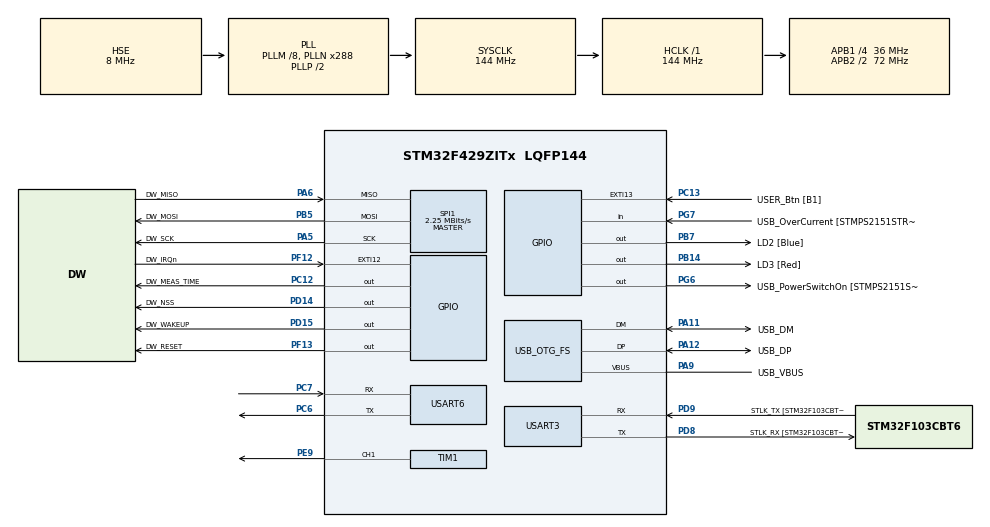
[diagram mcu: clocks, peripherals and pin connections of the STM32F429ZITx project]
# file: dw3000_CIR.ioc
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Dma.Request0=USART3_RX
Dma.Request1=USART3_TX
Dma.USART3_RX.0.Direction=DMA_PERIPH_TO_MEMORY
Dma.USART3_RX.0.FIFOMode=DMA_FIFOMODE_DISABLE
Dma.USART3_RX.0.Instance=DMA1_Stream1
Dma.USART3_RX.0.MemDataAlignment=DMA_MDATAALIGN_BYTE
Dma.USART3_RX.0.MemInc=DMA_MINC_ENABLE
Dma.USART3_RX.0.Mode=DMA_NORMAL
Dma.USART3_RX.0.PeriphDataAlignment=DMA_PDATAALIGN_BYTE
Dma.USART3_RX.0.PeriphInc=DMA_PINC_DISABLE
Dma.USART3_RX.0.Priority=DMA_PRIORITY_LOW
Dma.USART3_TX.1.Direction=DMA_MEMORY_TO_PERIPH
Dma.USART3_TX.1.FIFOMode=DMA_FIFOMODE_DISABLE
Dma.USART3_TX.1.Instance=DMA1_Stream3
Dma.USART3_TX.1.MemDataAlignment=DMA_MDATAALIGN_BYTE
Dma.USART3_TX.1.MemInc=DMA_MINC_ENABLE
Dma.USART3_TX.1.Mode=DMA_NORMAL
Dma.USART3_TX.1.PeriphDataAlignment=DMA_PDATAALIGN_BYTE
Dma.USART3_TX.1.PeriphInc=DMA_PINC_DISABLE
Dma.USART3_TX.1.Priority=DMA_PRIORITY_LOW
Mcu.Family=STM32F4
Mcu.Name=STM32F429ZITx
Mcu.Package=LQFP144
Mcu.UserConstants=LWIP_TIMEVAL_PRIVATE,0
NVIC.DMA1_Stream1_IRQn=true\:5\:0\:true\:true\:true\:2\:true\:true
NVIC.DMA1_Stream3_IRQn=true\:5\:0\:true\:true\:true\:3\:true\:true
NVIC.OTG_FS_IRQn=true\:0\:0\:false\:false\:true\:true\:true
NVIC.PriorityGroup=NVIC_PRIORITYGROUP_4
NVIC.TIM1_CC_IRQn=true\:5\:0\:true\:true\:true\:8\:true\:true
NVIC.TIM6_DAC_IRQn=true\:0\:0\:false\:false\:true\:true\:true
NVIC.TimeBase=TIM6_DAC_IRQn
NVIC.TimeBaseIP=TIM6
NVIC.USART3_IRQn=true\:5\:0\:true\:true\:true\:1\:true\:true
PA1.Signal=ETH_REF_CLK
PA10.GPIO_Label=USB_ID
PA10.Signal=USB_OTG_FS_ID
PA11.GPIO_Label=USB_DM
PA11.Mode=Device_Only
PA11.Signal=USB_OTG_FS_DM
PA12.GPIO_Label=USB_DP
PA12.Mode=Device_Only
PA12.Signal=USB_OTG_FS_DP
PA13.GPIO_Label=TMS
PA13.Mode=Serial_Wire
PA13.Signal=SYS_JTMS-SWDIO
PA14.GPIO_Label=TCK
PA14.Mode=Serial_Wire
PA14.Signal=SYS_JTCK-SWCLK
PA2.GPIO_Label=RMII_MDIO [LAN8742A-CZ-TR_MDIO]
PA2.Signal=ETH_MDIO
PA5.GPIO_Label=DW_SCK
PA5.Mode=Full_Duplex_Master
PA5.Signal=SPI1_SCK
PA6.GPIO_Label=DW_MISO
PA6.Mode=Full_Duplex_Master
PA6.Signal=SPI1_MISO
PA7.Signal=ETH_CRS_DV
PA8.GPIO_Label=USB_SOF [TP1]
PA8.Signal=USB_OTG_FS_SOF
PA9.GPIO_Label=USB_VBUS
PA9.Mode=Activate_VBUS
PA9.Signal=USB_OTG_FS_VBUS
PB13.GPIO_Label=RMII_TXD1 [LAN8742A-CZ-TR_TXD1]
PB13.Signal=ETH_TXD1
PB14.GPIO_Label=LD3 [Red]
PB14.Signal=GPIO_Output
PB5.GPIO_Label=DW_MOSI
PB5.Mode=Full_Duplex_Master
PB5.Signal=SPI1_MOSI
PB7.GPIO_Label=LD2 [Blue]
PB7.Signal=GPIO_Output
PC1.GPIO_Label=RMII_MDC [LAN8742A-CZ-TR_MDC]
PC1.Signal=ETH_MDC
PC12.GPIO_Label=DW_MEAS_TIME
PC12.GPIO_Speed=GPIO_SPEED_FREQ_MEDIUM
PC12.Signal=GPIO_Output
PC13.GPIO_Label=USER_Btn [B1]
PC13.Signal=GPXTI13
PC14/OSC32_IN.Mode=LSE-External-Oscillator
PC14/OSC32_IN.Signal=RCC_OSC32_IN
PC15/OSC32_OUT.Mode=LSE-External-Oscillator
PC15/OSC32_OUT.Signal=RCC_OSC32_OUT
PC4.GPIO_Label=RMII_RXD0 [LAN8742A-CZ-TR_RXD0]
PC4.Signal=ETH_RXD0
PC5.GPIO_Label=RMII_RXD1 [LAN8742A-CZ-TR_RXD1]
PC5.Signal=ETH_RXD1
PC6.Mode=Asynchronous
PC6.Signal=USART6_TX
PC7.Mode=Asynchronous
PC7.Signal=USART6_RX
PD14.GPIO_Label=DW_NSS
PD14.GPIO_PuPd=GPIO_PULLUP
PD14.GPIO_Speed=GPIO_SPEED_FREQ_MEDIUM
PD14.PinState=GPIO_PIN_SET
PD14.Signal=GPIO_Output
PD15.GPIO_Label=DW_WAKEUP
PD15.GPIO_Speed=GPIO_SPEED_FREQ_MEDIUM
PD15.Signal=GPIO_Output
PD8.GPIO_Label=STLK_RX [STM32F103CBT6_PA3]
PD8.Mode=Asynchronous
PD8.Signal=USART3_TX
PD9.GPIO_Label=STLK_TX [STM32F103CBT6_PA2]
PD9.Mode=Asynchronous
PD9.Signal=USART3_RX
PE9.Signal=S_TIM1_CH1
PF12.GPIO_Label=DW_IRQn
PF12.GPIO_PuPd=GPIO_PULLDOWN
PF12.Signal=GPXTI12
PF13.GPIO_Label=DW_RESET
PF13.GPIO_ModeDefaultOutputPP=GPIO_MODE_OUTPUT_OD
PF13.GPIO_Speed=GPIO_SPEED_FREQ_MEDIUM
PF13.Signal=GPIO_Output
PG11.GPIO_Label=RMII_TX_EN [LAN8742A-CZ-TR_TXEN]
PG11.Signal=ETH_TX_EN
PG13.GPIO_Label=RMII_TXD0 [LAN8742A-CZ-TR_TXD0]
PG13.Signal=ETH_TXD0
PG6.GPIO_Label=USB_PowerSwitchOn [STMPS2151STR_EN]
PG6.Signal=GPIO_Output
PG7.GPIO_Label=USB_OverCurrent [STMPS2151STR_FAULT]
PG7.Signal=GPIO_Input
PH0/OSC_IN.GPIO_Label=MCO [STM32F103CBT6_PA8]
PH0/OSC_IN.Mode=HSE-External-Clock-Source
PH0/OSC_IN.Signal=RCC_OSC_IN
PH1/OSC_OUT.Mode=HSE-External-Clock-Source
PH1/OSC_OUT.Signal=RCC_OSC_OUT
ProjectManager.HeapSize=0x200
ProjectManager.StackSize=0x400
ProjectManager.TargetToolchain=SW4STM32
RCC.48MHZClocksFreq_Value=48000000
RCC.AHBFreq_Value=144000000
RCC.APB1CLKDivider=RCC_HCLK_DIV4
RCC.APB1Freq_Value=36000000
RCC.APB1TimFreq_Value=72000000
RCC.APB2CLKDivider=RCC_HCLK_DIV2
RCC.APB2Freq_Value=72000000
RCC.APB2TimFreq_Value=144000000
RCC.CortexFreq_Value=144000000
RCC.HCLKFreq_Value=144000000
RCC.HSE_VALUE=8000000
RCC.HSI_VALUE=16000000
RCC.PLLM=8
RCC.PLLMUL=RCC_PLL_MUL9
RCC.PLLN=288
RCC.PLLQ=6
RCC.PRESCALERUSB=RCC_USBCLKSOURCE_PLL_DIV1_5
RCC.SYSCLKFreq_VALUE=144000000
RCC.SYSCLKSource=RCC_SYSCLKSOURCE_PLLCLK
RCC.SYSCLKSourceVirtual=RCC_SYSCLKSOURCE_PLLCLK
RCC.USBFreq_Value=48000000
RCC.VCOOutputFreq_Value=288000000
SH.S_TIM1_CH1.0=TIM1_CH1,Output Compare1 CH1
SPI1.BaudRatePrescaler=SPI_BAUDRATEPRESCALER_32
SPI1.CalculateBaudRate=2.25 MBits/s
SPI1.Direction=SPI_DIRECTION_2LINES
SPI1.Mode=SPI_MODE_MASTER
SPI1.VirtualType=VM_MASTER
TIM1.Channel-Output\ Compare1\ CH1=TIM_CHANNEL_1
TIM1.ClockDivision=TIM_CLOCKDIVISION_DIV2
TIM1.Period=65535
USART3.VirtualMode=VM_ASYNC
USART6.VirtualMode=VM_ASYNC
USB_DEVICE.CLASS_NAME_FS=CDC
USB_DEVICE.VirtualMode-CDC_FS=Cdc
USB_DEVICE.VirtualModeFS=Cdc_FS
USB_OTG_FS.VirtualMode=Device_Only
VP_RNG_VS_RNG.Mode=RNG_Activate
VP_SYS_VS_tim6.Mode=TIM6
VP_TIM1_VS_ClockSourceINT.Mode=Internal
VP_TIM1_VS_ClockSourceITR.Mode=TriggerSource_ITR0
VP_TIM1_VS_ControllerModeTrigger.Mode=Trigger Mode
VP_USB_DEVICE_VS_USB_DEVICE_CDC_FS.Mode=CDC_FS
board=NUCLEO-F429ZI

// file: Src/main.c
/* USER CODE BEGIN Header */
/**
  ******************************************************************************
  * @file           : main.c
  * @brief          : Main program body
  ******************************************************************************
  * @attention
  *
  * <h2><center>&copy; Copyright (c) 2021 STMicroelectronics.
  * All rights reserved.</center></h2>
  *
  * This software component is licensed by ST under Ultimate Liberty license
  * SLA0044, the "License"; You may not use this file except in compliance with
  * the License. You may obtain a copy of the License at:
  *                             www.st.com/SLA0044
  *
  ******************************************************************************
  */
/* USER CODE END Header */
#include <main.h>
#include <stm32f4xx_hal.h>
#include <usb_device.h>
#include <port.h>
#include "examples_defines.h"

RNG_HandleTypeDef hrng;

SPI_HandleTypeDef hspi1;

TIM_HandleTypeDef htim1;

UART_HandleTypeDef huart3;
UART_HandleTypeDef huart6;
DMA_HandleTypeDef hdma_usart3_rx;
DMA_HandleTypeDef hdma_usart3_tx;

/* USER CODE BEGIN PV */
#define UNIT_TEST 0
/* USER CODE END PV */

void SystemClock_Config(void);
static void MX_GPIO_Init(void);
static void MX_DMA_Init(void);
static void MX_TIM1_Init(void);
static void MX_USART3_UART_Init(void);
static void MX_SPI1_Init(void);
static void MX_RNG_Init(void);
static void MX_USART6_UART_Init(void);
static void MX_NVIC_Init(void);

void HAL_TIM_MspPostInit(TIM_HandleTypeDef *htim);

extern example_ptr example_pointer;

extern int unit_test_main(void);
extern uint8_t CDC_Transmit_FS(uint8_t* Buf, uint16_t Len);

/*! ------------------------------------------------------------------------------------------------------------------
* @fn test_run_info()
*
* @brief  This gets run info from a test and sends it through virtual COM port.
*
* @param data - Message data, this data should be NULL string.
*
* output parameters
*
* no return value
*/
void test_run_info(unsigned char *data)
{
    uint16_t    data_length;

    data_length=strlen((const char *)data);
    CDC_Transmit_FS(data, data_length);/*Transmit the data through USB - Virtual port*/
    //CDC_Transmit_FS((uint8_t*)"\n\r", 2);/*Transmit end of line through USB - Virtual port*/
}

int main(void)
{
  /* MCU Configuration--------------------------------------------------------*/

  /* Reset of all peripherals, Initializes the Flash interface and the Systick. */
  HAL_Init();

  /* Configure the system clock */
  SystemClock_Config();

  /* Initialize all configured peripherals */
  MX_GPIO_Init();
  MX_DMA_Init();
  MX_TIM1_Init();
  MX_USART3_UART_Init();
  MX_USB_DEVICE_Init();
  MX_SPI1_Init();
  MX_RNG_Init();
  MX_USART6_UART_Init();

  /* Initialize interrupts */
  MX_NVIC_Init();

  /* Infinite loop */
  /* USER CODE BEGIN WHILE */
  while (1)
  {
    /* USER CODE END WHILEafafs */
	 ss_twr_anchor();

  }
}

void SystemClock_Config(void)
{
  RCC_OscInitTypeDef RCC_OscInitStruct = {0};
  RCC_ClkInitTypeDef RCC_ClkInitStruct = {0};

  /** Configure the main internal regulator output voltage
  */
  __HAL_RCC_PWR_CLK_ENABLE();
  __HAL_PWR_VOLTAGESCALING_CONFIG(PWR_REGULATOR_VOLTAGE_SCALE1);
  /** Initializes the RCC Oscillators according to the specified parameters
  * in the RCC_OscInitTypeDef structure.
  */
  RCC_OscInitStruct.OscillatorType = RCC_OSCILLATORTYPE_HSE;
  RCC_OscInitStruct.HSEState = RCC_HSE_BYPASS;
  RCC_OscInitStruct.PLL.PLLState = RCC_PLL_ON;
  RCC_OscInitStruct.PLL.PLLSource = RCC_PLLSOURCE_HSE;
  RCC_OscInitStruct.PLL.PLLM = 8;
  RCC_OscInitStruct.PLL.PLLN = 288;
  RCC_OscInitStruct.PLL.PLLP = RCC_PLLP_DIV2;
  RCC_OscInitStruct.PLL.PLLQ = 6;
  if (HAL_RCC_OscConfig(&RCC_OscInitStruct) != HAL_OK)
  {
    Error_Handler();
  }
  /** Initializes the CPU, AHB and APB buses clocks
  */
  RCC_ClkInitStruct.ClockType = RCC_CLOCKTYPE_HCLK|RCC_CLOCKTYPE_SYSCLK
                              |RCC_CLOCKTYPE_PCLK1|RCC_CLOCKTYPE_PCLK2;
  RCC_ClkInitStruct.SYSCLKSource = RCC_SYSCLKSOURCE_PLLCLK;
  RCC_ClkInitStruct.AHBCLKDivider = RCC_SYSCLK_DIV1;
  RCC_ClkInitStruct.APB1CLKDivider = RCC_HCLK_DIV4;
  RCC_ClkInitStruct.APB2CLKDivider = RCC_HCLK_DIV2;

  if (HAL_RCC_ClockConfig(&RCC_ClkInitStruct, FLASH_LATENCY_4) != HAL_OK)
  {
    Error_Handler();
  }
}

/**
  * @brief NVIC Configuration.
  * @retval None
  */
static void MX_NVIC_Init(void)
{
  /* USART3_IRQn interrupt configuration */
  HAL_NVIC_SetPriority(USART3_IRQn, 5, 0);
  HAL_NVIC_EnableIRQ(USART3_IRQn);
  /* DMA1_Stream1_IRQn interrupt configuration */
  HAL_NVIC_SetPriority(DMA1_Stream1_IRQn, 5, 0);
  HAL_NVIC_EnableIRQ(DMA1_Stream1_IRQn);
  /* DMA1_Stream3_IRQn interrupt configuration */
  HAL_NVIC_SetPriority(DMA1_Stream3_IRQn, 5, 0);
  HAL_NVIC_EnableIRQ(DMA1_Stream3_IRQn);
  /* TIM1_CC_IRQn interrupt configuration */
  HAL_NVIC_SetPriority(TIM1_CC_IRQn, 5, 0);
  HAL_NVIC_EnableIRQ(TIM1_CC_IRQn);
}

static void MX_RNG_Init(void)
{

  hrng.Instance = RNG;
  if (HAL_RNG_Init(&hrng) != HAL_OK)
  {
    Error_Handler();
  }

}

static void MX_SPI1_Init(void)
{

  /* SPI1 parameter configuration*/
  hspi1.Instance = SPI1;
  hspi1.Init.Mode = SPI_MODE_MASTER;
  hspi1.Init.Direction = SPI_DIRECTION_2LINES;
  hspi1.Init.DataSize = SPI_DATASIZE_8BIT;
  hspi1.Init.CLKPolarity = SPI_POLARITY_LOW;
  hspi1.Init.CLKPhase = SPI_PHASE_1EDGE;
  hspi1.Init.NSS = SPI_NSS_SOFT;
  hspi1.Init.BaudRatePrescaler = SPI_BAUDRATEPRESCALER_32;
  hspi1.Init.FirstBit = SPI_FIRSTBIT_MSB;
  hspi1.Init.TIMode = SPI_TIMODE_DISABLE;
  hspi1.Init.CRCCalculation = SPI_CRCCALCULATION_DISABLE;
  hspi1.Init.CRCPolynomial = 10;
  if (HAL_SPI_Init(&hspi1) != HAL_OK)
  {
    Error_Handler();
  }

}

static void MX_TIM1_Init(void)
{

  TIM_ClockConfigTypeDef sClockSourceConfig = {0};
  TIM_SlaveConfigTypeDef sSlaveConfig = {0};
  TIM_MasterConfigTypeDef sMasterConfig = {0};
  TIM_OC_InitTypeDef sConfigOC = {0};
  TIM_BreakDeadTimeConfigTypeDef sBreakDeadTimeConfig = {0};

  htim1.Instance = TIM1;
  htim1.Init.Prescaler = 0;
  htim1.Init.CounterMode = TIM_COUNTERMODE_UP;
  htim1.Init.Period = 65535;
  htim1.Init.ClockDivision = TIM_CLOCKDIVISION_DIV2;
  htim1.Init.RepetitionCounter = 0;
  htim1.Init.AutoReloadPreload = TIM_AUTORELOAD_PRELOAD_DISABLE;
  if (HAL_TIM_Base_Init(&htim1) != HAL_OK)
  {
    Error_Handler();
  }
  sClockSourceConfig.ClockSource = TIM_CLOCKSOURCE_INTERNAL;
  if (HAL_TIM_ConfigClockSource(&htim1, &sClockSourceConfig) != HAL_OK)
  {
    Error_Handler();
  }
  if (HAL_TIM_OC_Init(&htim1) != HAL_OK)
  {
    Error_Handler();
  }
  sSlaveConfig.SlaveMode = TIM_SLAVEMODE_TRIGGER;
  sSlaveConfig.InputTrigger = TIM_TS_ITR0;
  if (HAL_TIM_SlaveConfigSynchro(&htim1, &sSlaveConfig) != HAL_OK)
  {
    Error_Handler();
  }
  sMasterConfig.MasterOutputTrigger = TIM_TRGO_RESET;
  sMasterConfig.MasterSlaveMode = TIM_MASTERSLAVEMODE_DISABLE;
  if (HAL_TIMEx_MasterConfigSynchronization(&htim1, &sMasterConfig) != HAL_OK)
  {
    Error_Handler();
  }
  sConfigOC.OCMode = TIM_OCMODE_TIMING;
  sConfigOC.Pulse = 0;
  sConfigOC.OCPolarity = TIM_OCPOLARITY_HIGH;
  sConfigOC.OCNPolarity = TIM_OCNPOLARITY_HIGH;
  sConfigOC.OCFastMode = TIM_OCFAST_DISABLE;
  sConfigOC.OCIdleState = TIM_OCIDLESTATE_RESET;
  sConfigOC.OCNIdleState = TIM_OCNIDLESTATE_RESET;
  if (HAL_TIM_OC_ConfigChannel(&htim1, &sConfigOC, TIM_CHANNEL_1) != HAL_OK)
  {
    Error_Handler();
  }
  sBreakDeadTimeConfig.OffStateRunMode = TIM_OSSR_DISABLE;
  sBreakDeadTimeConfig.OffStateIDLEMode = TIM_OSSI_DISABLE;
  sBreakDeadTimeConfig.LockLevel = TIM_LOCKLEVEL_OFF;
  sBreakDeadTimeConfig.DeadTime = 0;
  sBreakDeadTimeConfig.BreakState = TIM_BREAK_DISABLE;
  sBreakDeadTimeConfig.BreakPolarity = TIM_BREAKPOLARITY_HIGH;
  sBreakDeadTimeConfig.AutomaticOutput = TIM_AUTOMATICOUTPUT_DISABLE;
  if (HAL_TIMEx_ConfigBreakDeadTime(&htim1, &sBreakDeadTimeConfig) != HAL_OK)
  {
    Error_Handler();
  }
  HAL_TIM_MspPostInit(&htim1);

}

static void MX_USART3_UART_Init(void)
{

  huart3.Instance = USART3;
  huart3.Init.BaudRate = 115200;
  huart3.Init.WordLength = UART_WORDLENGTH_8B;
  huart3.Init.StopBits = UART_STOPBITS_1;
  huart3.Init.Parity = UART_PARITY_NONE;
  huart3.Init.Mode = UART_MODE_TX_RX;
  huart3.Init.HwFlowCtl = UART_HWCONTROL_NONE;
  huart3.Init.OverSampling = UART_OVERSAMPLING_16;
  if (HAL_UART_Init(&huart3) != HAL_OK)
  {
    Error_Handler();
  }

}

static void MX_USART6_UART_Init(void)
{

  huart6.Instance = USART6;
  huart6.Init.BaudRate = 115200;
  huart6.Init.WordLength = UART_WORDLENGTH_8B;
  huart6.Init.StopBits = UART_STOPBITS_1;
  huart6.Init.Parity = UART_PARITY_NONE;
  huart6.Init.Mode = UART_MODE_TX_RX;
  huart6.Init.HwFlowCtl = UART_HWCONTROL_NONE;
  huart6.Init.OverSampling = UART_OVERSAMPLING_16;
  if (HAL_UART_Init(&huart6) != HAL_OK)
  {
    Error_Handler();
  }

}

static void MX_DMA_Init(void)
{

  /* DMA controller clock enable */
  __HAL_RCC_DMA1_CLK_ENABLE();

}

static void MX_GPIO_Init(void)
{
  GPIO_InitTypeDef GPIO_InitStruct = {0};

  /* GPIO Ports Clock Enable */
  __HAL_RCC_GPIOC_CLK_ENABLE();
  __HAL_RCC_GPIOH_CLK_ENABLE();
  __HAL_RCC_GPIOA_CLK_ENABLE();
  __HAL_RCC_GPIOF_CLK_ENABLE();
  __HAL_RCC_GPIOE_CLK_ENABLE();
  __HAL_RCC_GPIOB_CLK_ENABLE();
  __HAL_RCC_GPIOD_CLK_ENABLE();
  __HAL_RCC_GPIOG_CLK_ENABLE();

  /*Configure GPIO pin Output Level */
  HAL_GPIO_WritePin(DW_RESET_GPIO_Port, DW_RESET_Pin, GPIO_PIN_RESET);

  /*Configure GPIO pin Output Level */
  HAL_GPIO_WritePin(GPIOB, LD3_Pin|LD2_Pin, GPIO_PIN_RESET);

  /*Configure GPIO pin Output Level */
  HAL_GPIO_WritePin(DW_NSS_GPIO_Port, DW_NSS_Pin, GPIO_PIN_SET);

  /*Configure GPIO pin Output Level */
  HAL_GPIO_WritePin(DW_WAKEUP_GPIO_Port, DW_WAKEUP_Pin, GPIO_PIN_RESET);

  /*Configure GPIO pin Output Level */
  HAL_GPIO_WritePin(USB_PowerSwitchOn_GPIO_Port, USB_PowerSwitchOn_Pin, GPIO_PIN_RESET);

  /*Configure GPIO pin Output Level */
  HAL_GPIO_WritePin(DW_MEAS_TIME_GPIO_Port, DW_MEAS_TIME_Pin, GPIO_PIN_RESET);

  /*Configure GPIO pin : USER_Btn_Pin */
  GPIO_InitStruct.Pin = USER_Btn_Pin;
  GPIO_InitStruct.Mode = GPIO_MODE_IT_RISING;
  GPIO_InitStruct.Pull = GPIO_NOPULL;
  HAL_GPIO_Init(USER_Btn_GPIO_Port, &GPIO_InitStruct);

  /*Configure GPIO pins : RMII_MDC_Pin RMII_RXD0_Pin RMII_RXD1_Pin */
  GPIO_InitStruct.Pin = RMII_MDC_Pin|RMII_RXD0_Pin|RMII_RXD1_Pin;
  GPIO_InitStruct.Mode = GPIO_MODE_AF_PP;
  GPIO_InitStruct.Pull = GPIO_NOPULL;
  GPIO_InitStruct.Speed = GPIO_SPEED_FREQ_VERY_HIGH;
  GPIO_InitStruct.Alternate = GPIO_AF11_ETH;
  HAL_GPIO_Init(GPIOC, &GPIO_InitStruct);

  /*Configure GPIO pins : PA1 RMII_MDIO_Pin PA7 */
  GPIO_InitStruct.Pin = GPIO_PIN_1|RMII_MDIO_Pin|GPIO_PIN_7;
  GPIO_InitStruct.Mode = GPIO_MODE_AF_PP;
  GPIO_InitStruct.Pull = GPIO_NOPULL;
  GPIO_InitStruct.Speed = GPIO_SPEED_FREQ_VERY_HIGH;
  GPIO_InitStruct.Alternate = GPIO_AF11_ETH;
  HAL_GPIO_Init(GPIOA, &GPIO_InitStruct);

  /*Configure GPIO pin : DW_IRQn_Pin */
  GPIO_InitStruct.Pin = DW_IRQn_Pin;
  GPIO_InitStruct.Mode = GPIO_MODE_IT_RISING;
  GPIO_InitStruct.Pull = GPIO_PULLDOWN;
  HAL_GPIO_Init(DW_IRQn_GPIO_Port, &GPIO_InitStruct);

  /*Configure GPIO pin : DW_RESET_Pin */
  GPIO_InitStruct.Pin = DW_RESET_Pin;
  GPIO_InitStruct.Mode = GPIO_MODE_OUTPUT_OD;
  GPIO_InitStruct.Pull = GPIO_NOPULL;
  GPIO_InitStruct.Speed = GPIO_SPEED_FREQ_MEDIUM;
  HAL_GPIO_Init(DW_RESET_GPIO_Port, &GPIO_InitStruct);

  /*Configure GPIO pin : RMII_TXD1_Pin */
  GPIO_InitStruct.Pin = RMII_TXD1_Pin;
  GPIO_InitStruct.Mode = GPIO_MODE_AF_PP;
  GPIO_InitStruct.Pull = GPIO_NOPULL;
  GPIO_InitStruct.Speed = GPIO_SPEED_FREQ_VERY_HIGH;
  GPIO_InitStruct.Alternate = GPIO_AF11_ETH;
  HAL_GPIO_Init(RMII_TXD1_GPIO_Port, &GPIO_InitStruct);

  /*Configure GPIO pins : LD3_Pin LD2_Pin */
  GPIO_InitStruct.Pin = LD3_Pin|LD2_Pin;
  GPIO_InitStruct.Mode = GPIO_MODE_OUTPUT_PP;
  GPIO_InitStruct.Pull = GPIO_NOPULL;
  GPIO_InitStruct.Speed = GPIO_SPEED_FREQ_LOW;
  HAL_GPIO_Init(GPIOB, &GPIO_InitStruct);

  /*Configure GPIO pin : DW_NSS_Pin */
  GPIO_InitStruct.Pin = DW_NSS_Pin;
  GPIO_InitStruct.Mode = GPIO_MODE_OUTPUT_PP;
  GPIO_InitStruct.Pull = GPIO_PULLUP;
  GPIO_InitStruct.Speed = GPIO_SPEED_FREQ_MEDIUM;
  HAL_GPIO_Init(DW_NSS_GPIO_Port, &GPIO_InitStruct);

  /*Configure GPIO pin : DW_WAKEUP_Pin */
  GPIO_InitStruct.Pin = DW_WAKEUP_Pin;
  GPIO_InitStruct.Mode = GPIO_MODE_OUTPUT_PP;
  GPIO_InitStruct.Pull = GPIO_NOPULL;
  GPIO_InitStruct.Speed = GPIO_SPEED_FREQ_MEDIUM;
  HAL_GPIO_Init(DW_WAKEUP_GPIO_Port, &GPIO_InitStruct);

  /*Configure GPIO pin : USB_PowerSwitchOn_Pin */
  GPIO_InitStruct.Pin = USB_PowerSwitchOn_Pin;
  GPIO_InitStruct.Mode = GPIO_MODE_OUTPUT_PP;
  GPIO_InitStruct.Pull = GPIO_NOPULL;
  GPIO_InitStruct.Speed = GPIO_SPEED_FREQ_LOW;
  HAL_GPIO_Init(USB_PowerSwitchOn_GPIO_Port, &GPIO_InitStruct);

  /*Configure GPIO pin : USB_OverCurrent_Pin */
  GPIO_InitStruct.Pin = USB_OverCurrent_Pin;
  GPIO_InitStruct.Mode = GPIO_MODE_INPUT;
  GPIO_InitStruct.Pull = GPIO_NOPULL;
  HAL_GPIO_Init(USB_OverCurrent_GPIO_Port, &GPIO_InitStruct);

  /*Configure GPIO pin : DW_MEAS_TIME_Pin */
  GPIO_InitStruct.Pin = DW_MEAS_TIME_Pin;
  GPIO_InitStruct.Mode = GPIO_MODE_OUTPUT_PP;
  GPIO_InitStruct.Pull = GPIO_NOPULL;
  GPIO_InitStruct.Speed = GPIO_SPEED_FREQ_MEDIUM;
  HAL_GPIO_Init(DW_MEAS_TIME_GPIO_Port, &GPIO_InitStruct);

  /*Configure GPIO pins : RMII_TX_EN_Pin RMII_TXD0_Pin */
  GPIO_InitStruct.Pin = RMII_TX_EN_Pin|RMII_TXD0_Pin;
  GPIO_InitStruct.Mode = GPIO_MODE_AF_PP;
  GPIO_InitStruct.Pull = GPIO_NOPULL;
  GPIO_InitStruct.Speed = GPIO_SPEED_FREQ_VERY_HIGH;
  GPIO_InitStruct.Alternate = GPIO_AF11_ETH;
  HAL_GPIO_Init(GPIOG, &GPIO_InitStruct);

}

 /**
  * @brief  Period elapsed callback in non blocking mode
  * @note   This function is called  when TIM6 interrupt took place, inside
  * HAL_TIM_IRQHandler(). It makes a direct call to HAL_IncTick() to increment
  * a global variable "uwTick" used as application time base.
  * @param  htim : TIM handle
  * @retval None
  */
void HAL_TIM_PeriodElapsedCallback(TIM_HandleTypeDef *htim)
{
  if (htim->Instance == TIM6) {
    HAL_IncTick();
  }
}

void Error_Handler(void)
{
  __disable_irq();
  while (1)
  {
  }
}

/************************ (C) COPYRIGHT STMicroelectronics *****END OF FILE****/
